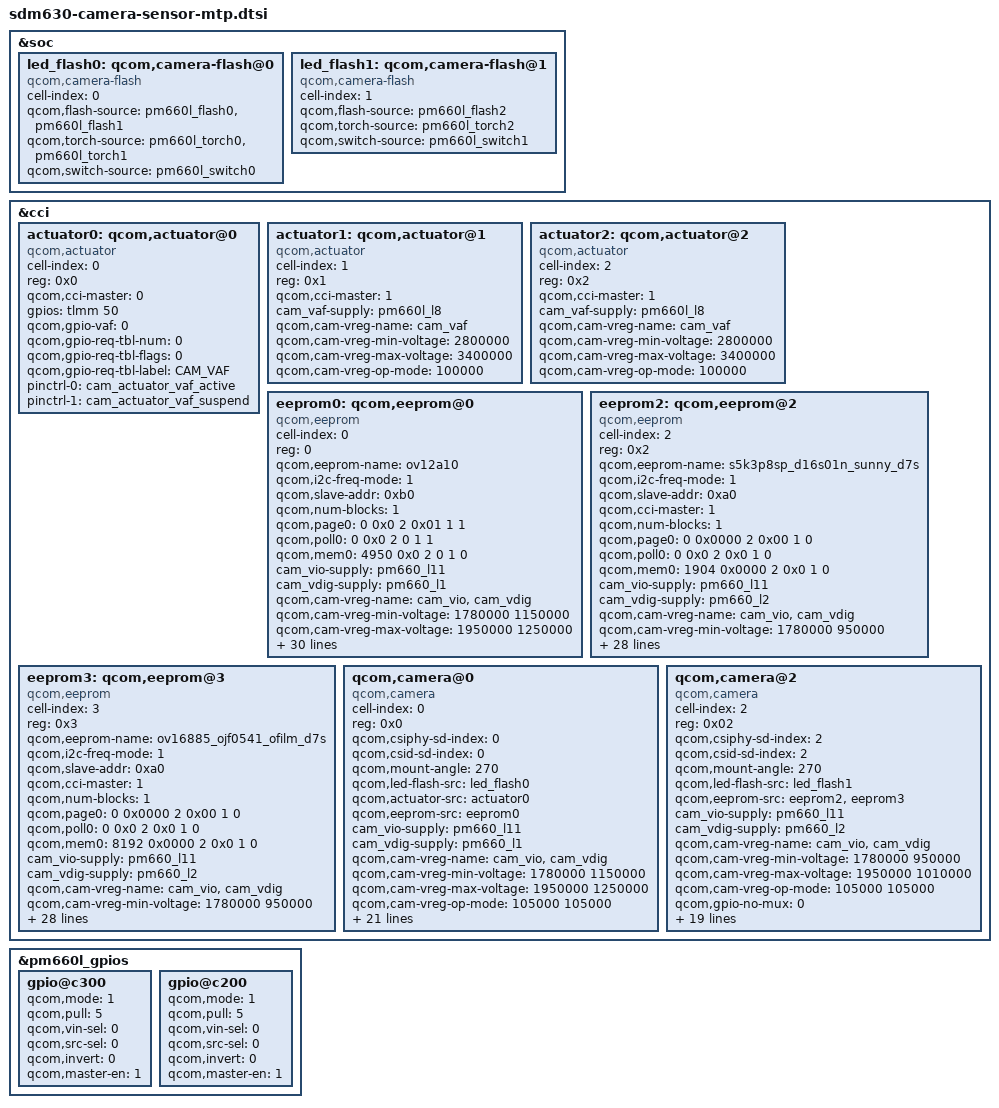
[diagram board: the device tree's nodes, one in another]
/*
 * Copyright (c) 2017, The Linux Foundation. All rights reserved.
 * Copyright (C) 2018 XiaoMi, Inc.
 *
 * This program is free software; you can redistribute it and/or modify
 * it under the terms of the GNU General Public License version 2 and
 * only version 2 as published by the Free Software Foundation.
 *
 * This program is distributed in the hope that it will be useful,
 * but WITHOUT ANY WARRANTY; without even the implied warranty of
 * MERCHANTABILITY or FITNESS FOR A PARTICULAR PURPOSE.  See the
 * GNU General Public License for more details.
 */

&soc {
	led_flash0: qcom,camera-flash@0 {
		cell-index = <0>;
		compatible = "qcom,camera-flash";
		qcom,flash-source = <&pm660l_flash0 &pm660l_flash1>;
		qcom,torch-source = <&pm660l_torch0 &pm660l_torch1>;
		qcom,switch-source = <&pm660l_switch0>;
		status = "ok";
	};

	led_flash1: qcom,camera-flash@1 {
		cell-index = <1>;
		compatible = "qcom,camera-flash";
		qcom,flash-source = <&pm660l_flash2>;
		qcom,torch-source = <&pm660l_torch2>;
		qcom,switch-source = <&pm660l_switch1>;
		status = "ok";
	};
};

&cci {
	actuator0: qcom,actuator@0 {
		cell-index = <0>;
		reg = <0x0>;
		compatible = "qcom,actuator";
		qcom,cci-master = <0>;
		gpios = <&tlmm 50 0>;
		qcom,gpio-vaf = <0>;
		qcom,gpio-req-tbl-num = <0>;
		qcom,gpio-req-tbl-flags = <0>;
		qcom,gpio-req-tbl-label = "CAM_VAF";
		pinctrl-names = "cam_default", "cam_suspend";
		pinctrl-0 = <&cam_actuator_vaf_active>;
		pinctrl-1 = <&cam_actuator_vaf_suspend>;
	};

	actuator1: qcom,actuator@1 {
		cell-index = <1>;
		reg = <0x1>;
		compatible = "qcom,actuator";
		qcom,cci-master = <1>;
		cam_vaf-supply = <&pm660l_l8>;
		qcom,cam-vreg-name = "cam_vaf";
		qcom,cam-vreg-min-voltage = <2800000>;
		qcom,cam-vreg-max-voltage = <3400000>;
		qcom,cam-vreg-op-mode = <100000>;
	};

	actuator2: qcom,actuator@2 {
		cell-index = <2>;
		reg = <0x2>;
		compatible = "qcom,actuator";
		qcom,cci-master = <1>;
		cam_vaf-supply = <&pm660l_l8>;
		qcom,cam-vreg-name = "cam_vaf";
		qcom,cam-vreg-min-voltage = <2800000>;
		qcom,cam-vreg-max-voltage = <3400000>;
		qcom,cam-vreg-op-mode = <100000>;
	};

eeprom0: qcom,eeprom@0 {
		cell-index = <0>;
		reg = <0>;
		qcom,eeprom-name = "ov12a10";
		compatible = "qcom,eeprom";
		qcom,i2c-freq-mode = <1>;
		qcom,slave-addr = <0xb0>;
		qcom,num-blocks = <1>;
		qcom,page0 = <0 0x0 2 0x01 1 1>;
		qcom,poll0 = <0 0x0 2 0 1 1>;
		qcom,mem0 = <4950 0x0 2 0 1 0>;
		cam_vio-supply = <&pm660_l11>;
		cam_vdig-supply = <&pm660_l1>;
		qcom,cam-vreg-name = "cam_vio", "cam_vdig";
		qcom,cam-vreg-min-voltage = <1780000 1150000>;
		qcom,cam-vreg-max-voltage = <1950000 1250000>;
		qcom,cam-vreg-op-mode = <105000 105000>;
		qcom,gpio-no-mux = <0>;
		pinctrl-names = "cam_default", "cam_suspend";
		pinctrl-0 = <&cam_sensor_mclk0_active
				&cam_sensor_rear2_active>;
		pinctrl-1 = <&cam_sensor_mclk0_suspend
				&cam_sensor_rear2_suspend>;
		gpios = <&tlmm 32 0>,
			<&tlmm 48 0>,
			<&pm660l_gpios 4 0>,
			<&tlmm 51 0>,
			<&tlmm 50 0>;
		qcom,gpio-reset = <1>;
		qcom,gpio-vdig = <2>;
		qcom,gpio-vana = <3>;
		qcom,gpio-vaf = <4>;
		qcom,gpio-req-tbl-num = <0 1 2 3 4>;
		qcom,gpio-req-tbl-flags = <1 0 0 0 0>;
		qcom,gpio-req-tbl-label = "CAMIF_MCLK0",
					"CAM_RESET0",
					"CAM_VDIG",
					"CAM_VANA",
					"CAM_VAF";
		qcom,cam-power-seq-type = "sensor_vreg", "sensor_vreg", "sensor_gpio", "sensor_gpio",
				"sensor_gpio", "sensor_clk";
		qcom,cam-power-seq-val = "cam_vdig", "cam_vio", "sensor_gpio_vana", "sensor_gpio_vaf",
				"sensor_gpio_reset","sensor_cam_mclk";
		qcom,cam-power-seq-cfg-val = <1 1 1 1 1 24000000>;
		qcom,cam-power-seq-delay = <5 0 5 5 5 5>;
		qcom,sensor-position = <0>;
		qcom,sensor-mode = <0>;
		qcom,cci-master = <0>;
		status = "ok";
		clocks = <&clock_mmss MCLK0_CLK_SRC>,
				<&clock_mmss MMSS_CAMSS_MCLK0_CLK>;
		clock-names = "cam_src_clk", "cam_clk";
		qcom,clock-rates = <24000000 0>;
	};

	eeprom2: qcom,eeprom@2 {
		cell-index = <2>;
		reg = <0x2>;
		qcom,eeprom-name = "s5k3p8sp_d16s01n_sunny_d7s";
		compatible = "qcom,eeprom";
		qcom,i2c-freq-mode = <1>;
		qcom,slave-addr = <0xa0>;
		qcom,cci-master = <1>;
		qcom,num-blocks = <1>;

		qcom,page0 = <0 0x0000 2 0x00 1 0>;
		qcom,poll0 = <0 0x0 2 0x0 1 0>;
		qcom,mem0 = <1904 0x0000 2 0x0 1 0>;

		cam_vio-supply = <&pm660_l11>;
		cam_vdig-supply = <&pm660_l2>;
		qcom,cam-vreg-name = "cam_vio","cam_vdig";
		qcom,cam-vreg-min-voltage = <1780000 950000>;
		qcom,cam-vreg-max-voltage = <1950000 1010000>;
		qcom,cam-vreg-op-mode = <105000 105000>;
		qcom,gpio-no-mux = <0>;
		pinctrl-names = "cam_default", "cam_suspend";
		pinctrl-0 = <&cam_sensor_mclk1_active
				&cam_sensor_front_active>;
		pinctrl-1 = <&cam_sensor_mclk1_suspend
				&cam_sensor_front_suspend>;
		gpios = <&tlmm 33 0>,
			<&tlmm 47 0>,
			<&pm660_gpios 3 0>,
			<&tlmm 51 0>;
		qcom,gpio-reset = <1>;
		qcom,gpio-vdig = <2>;
		qcom,gpio-vana = <3>;
		qcom,gpio-req-tbl-num = <0 1 2 3>;
		qcom,gpio-req-tbl-flags = <1 0 0 0>;
		qcom,gpio-req-tbl-label = "CAMIF_MCLK1",
					"CAM_RESET1",
					"CAM_VDIG",
					"CAM_VANA";

		qcom,cam-power-seq-type = "sensor_vreg","sensor_vreg","sensor_gpio",
				"sensor_gpio","sensor_clk";
		qcom,cam-power-seq-val = "cam_vdig","cam_vio", "sensor_gpio_vana",
				"sensor_gpio_reset","sensor_cam_mclk";
		qcom,cam-power-seq-cfg-val = <1 1 1 1 24000000>;
		qcom,cam-power-seq-delay = <5 0 5 5 5>;

		qcom,sensor-mode = <0>;
		status = "ok";
		clocks = <&clock_mmss MCLK1_CLK_SRC>,
			<&clock_mmss MMSS_CAMSS_MCLK1_CLK>;
		clock-names = "cam_src_clk", "cam_clk";
		qcom,clock-rates = <24000000 0>;
	};

	eeprom3: qcom,eeprom@3 {
		cell-index = <3>;
		reg = <0x3>;
		qcom,eeprom-name = "ov16885_ojf0541_ofilm_d7s";
		compatible = "qcom,eeprom";
		qcom,i2c-freq-mode = <1>;
		qcom,slave-addr = <0xa0>;
		qcom,cci-master = <1>;
		qcom,num-blocks = <1>;

		qcom,page0 = <0 0x0000 2 0x00 1 0>;
		qcom,poll0 = <0 0x0 2 0x0 1 0>;
		qcom,mem0 = <8192 0x0000 2 0x0 1 0>;

		cam_vio-supply = <&pm660_l11>;
		cam_vdig-supply = <&pm660_l2>;
		qcom,cam-vreg-name = "cam_vio","cam_vdig";
		qcom,cam-vreg-min-voltage = <1780000 950000>;
		qcom,cam-vreg-max-voltage = <1950000 1010000>;
		qcom,cam-vreg-op-mode = <105000 105000>;
		qcom,gpio-no-mux = <0>;
		pinctrl-names = "cam_default", "cam_suspend";
		pinctrl-0 = <&cam_sensor_mclk1_active
				&cam_sensor_front_active>;
		pinctrl-1 = <&cam_sensor_mclk1_suspend
				&cam_sensor_front_suspend>;
		gpios = <&tlmm 33 0>,
				<&tlmm 47 0>,
				<&pm660_gpios 3 0>,
				<&tlmm 51 0>;
		qcom,gpio-reset = <1>;
		qcom,gpio-vdig = <2>;
		qcom,gpio-vana = <3>;
		qcom,gpio-req-tbl-num = <0 1 2 3>;
		qcom,gpio-req-tbl-flags = <1 0 0 0>;
		qcom,gpio-req-tbl-label = "CAMIF_MCLK1",
				"CAM_RESET1",
				"CAM_VDIG",
				"CAM_VANA";
		qcom,cam-power-seq-type = "sensor_vreg","sensor_vreg","sensor_gpio",
				"sensor_gpio","sensor_clk";
		qcom,cam-power-seq-val = "cam_vdig","cam_vio", "sensor_gpio_vana",
				"sensor_gpio_reset","sensor_cam_mclk";
		qcom,cam-power-seq-cfg-val = <1 1 1 1 24000000>;
		qcom,cam-power-seq-delay = <5 0 5 5 5>;

		qcom,sensor-mode = <0>;
		status = "ok";
		clocks = <&clock_mmss MCLK1_CLK_SRC>,
				<&clock_mmss MMSS_CAMSS_MCLK1_CLK>;
		clock-names = "cam_src_clk", "cam_clk";
		qcom,clock-rates = <24000000 0>;
	};

	qcom,camera@0 {
		cell-index = <0>;
		compatible = "qcom,camera";
		reg = <0x0>;
		qcom,csiphy-sd-index = <0>;
		qcom,csid-sd-index = <0>;
		qcom,mount-angle = <270>;
		qcom,led-flash-src = <&led_flash0>;
		qcom,actuator-src = <&actuator0>;
		qcom,eeprom-src = <&eeprom0>;
		cam_vio-supply = <&pm660_l11>;
		cam_vdig-supply = <&pm660_l1>;
		qcom,cam-vreg-name = "cam_vio", "cam_vdig";
		qcom,cam-vreg-min-voltage = <1780000 1150000>;
		qcom,cam-vreg-max-voltage = <1950000 1250000>;
		qcom,cam-vreg-op-mode = <105000 105000>;
		qcom,gpio-no-mux = <0>;
		pinctrl-names = "cam_default", "cam_suspend";
		pinctrl-0 = <&cam_sensor_mclk0_active
				 &cam_sensor_rear2_active>;
		pinctrl-1 = <&cam_sensor_mclk0_suspend
				 &cam_sensor_rear2_suspend>;
		gpios = <&tlmm 32 0>,
			<&tlmm 48 0>,
			<&pm660l_gpios 4 0>,
			<&tlmm 51 0>,
			<&tlmm 50 0>;
		qcom,gpio-reset = <1>;
		qcom,gpio-vdig = <2>;
		qcom,gpio-vana = <3>;
		qcom,gpio-vaf = <4>;
		qcom,gpio-req-tbl-num = <0 1 2 3 4>;
		qcom,gpio-req-tbl-flags = <1 0 0 0 0>;
		qcom,gpio-req-tbl-label = "CAMIF_MCLK0",
					"CAM_RESET0",
					"CAM_VDIG",
					"CAM_VANA",
					"CAM_VAF";
		qcom,sensor-position = <0>;
		qcom,sensor-mode = <0>;
		qcom,cci-master = <0>;
		status = "ok";
		clocks = <&clock_mmss MCLK0_CLK_SRC>,
				<&clock_mmss MMSS_CAMSS_MCLK0_CLK>;
		clock-names = "cam_src_clk", "cam_clk";
		qcom,clock-rates = <24000000 0>;
	};

	qcom,camera@2 {
		cell-index = <2>;
		compatible = "qcom,camera";
		reg = <0x02>;
		qcom,csiphy-sd-index = <2>;
		qcom,csid-sd-index = <2>;
		qcom,mount-angle = <270>;
		qcom,led-flash-src = <&led_flash1>;
		qcom,eeprom-src = <&eeprom2 &eeprom3>;
		cam_vio-supply = <&pm660_l11>;
		cam_vdig-supply = <&pm660_l2>;
		qcom,cam-vreg-name = "cam_vio", "cam_vdig";
		qcom,cam-vreg-min-voltage = <1780000 950000>;
		qcom,cam-vreg-max-voltage = <1950000 1010000>;
		qcom,cam-vreg-op-mode = <105000 105000>;
		qcom,gpio-no-mux = <0>;
		pinctrl-names = "cam_default", "cam_suspend";
		pinctrl-0 = <&cam_sensor_mclk1_active
				 &cam_sensor_front_active>;
		pinctrl-1 = <&cam_sensor_mclk1_suspend
				 &cam_sensor_front_suspend>;
		gpios = <&tlmm 33 0>,
			<&tlmm 47 0>,
			<&pm660l_gpios 3 0>,
			<&tlmm 51 0>;
		qcom,gpio-reset = <1>;
		qcom,gpio-vdig = <2>;
		qcom,gpio-vana = <3>;
		qcom,gpio-req-tbl-num = <0 1 2 3>;
		qcom,gpio-req-tbl-flags = <1 0 0 0>;
		qcom,gpio-req-tbl-label = "CAMIF_MCLK1",
					"CAM_RESET1",
					"CAM_VDIG",
					"CAM_VANA";
		qcom,sensor-position = <1>;
		qcom,sensor-mode = <0>;
		qcom,cci-master = <1>;
		status = "ok";
		clocks = <&clock_mmss MCLK1_CLK_SRC>,
			<&clock_mmss MMSS_CAMSS_MCLK1_CLK>;
		clock-names = "cam_src_clk", "cam_clk";
		qcom,clock-rates = <24000000 0>;
	};

};

&pm660l_gpios {
	gpio@c300 { /* GPIO4 -CAMERA SENSOR 0 VDIG*/
		qcom,mode = <1>;                /* Output */
		qcom,pull = <5>;                /* No Pull */
		qcom,vin-sel = <0>;             /* VIN1 GPIO_LV */
		qcom,src-sel = <0>;             /* GPIO */
		qcom,invert = <0>;              /* Invert */
		qcom,master-en = <1>;           /* Enable GPIO */
		status = "ok";
	};

	gpio@c200 { /* GPIO3 -CAMERA SENSOR 2 VDIG*/
		qcom,mode = <1>;                /* Output */
		qcom,pull = <5>;                /* No Pull */
		qcom,vin-sel = <0>;             /* VIN1 GPIO_LV */
		qcom,src-sel = <0>;             /* GPIO */
		qcom,invert = <0>;              /* Invert */
		qcom,master-en = <1>;           /* Enable GPIO */
		status = "ok";
	};
};
